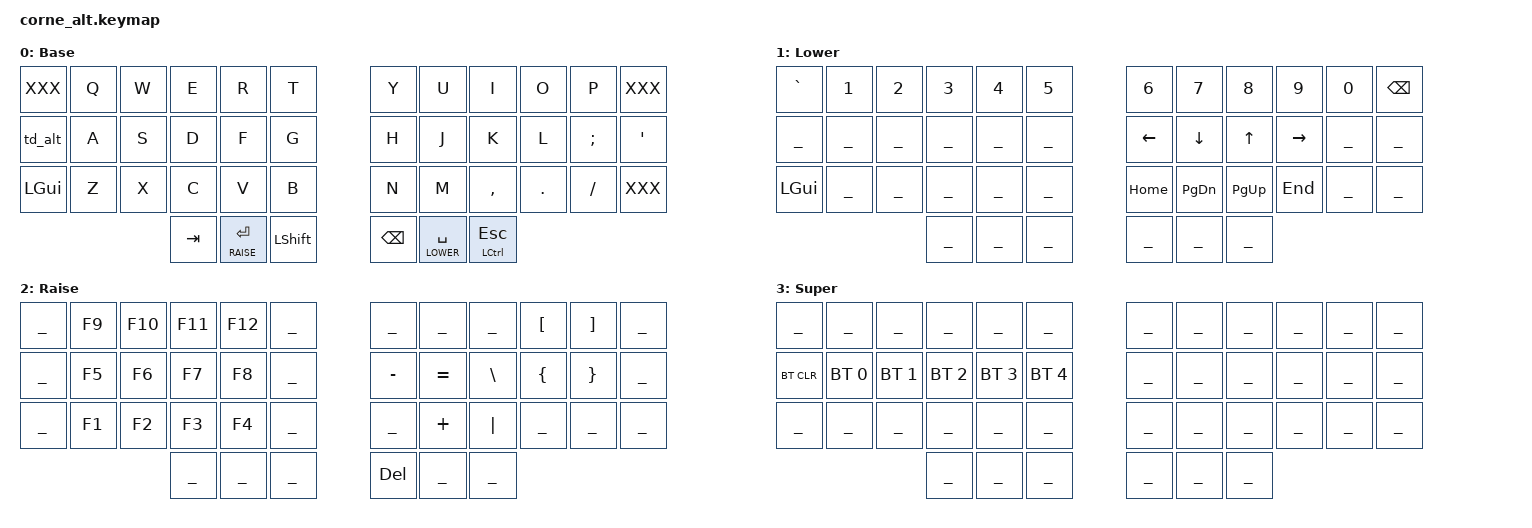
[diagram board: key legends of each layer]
/*
 * Copyright (c) 2020 The ZMK Contributors
 *
 * SPDX-License-Identifier: MIT
 */
 // https://caksoylar.github.io/keymap-drawer?keymap_yaml=H4sIAAAAAAAC_5WU23aTQBSG7_sU43hWGkNOLbhcS5qQtopGc7DWNCJNpk1WCCCQVbMivo0-g_e-mPPDdGxOrb3Il-GfvX82eza4zsyfxvoWIV8nY3vMZqe-Ew500vdDj9mhHzsxG4hdN4sllnHc6LTtKHBHsV38VrGLW3yLhRFsambd6FhtLAnZJl1v6roKoe8pxxFgAk2gDRwDHeAQaADvOJDXuzShluHG2DGAFlAD6sA-cAC8Al4DFvAceEivuOxPR9A-AR-BKvAB2APeAm8ABcgBz1aKaRsInvNOmF7MQoUMdf5EzihiNFFIazg6i2EYOH0m4lpYZ3GWf8FCxM35lVWNQ94dOLWqCe5gNY7MpmwecukXbhLx_x9pFhRVKHekUhDKS6kUhXJXKiWh3JNKWSj3pVIRymep7AjlgVR2hfJEKppQHkklL5THUBa6l83D9aQWO0uPu-ZfeOl8BOnQjM6HMb0aejvXA3_C0vE6JwNhzJfT1Nv0Buud08fJTjyeBUwnceh4UbLh_NcFiYFY3ZAjsryVXtIhcwdrB2UxAZU2jcOWufTK1TX-U_OAChSu6UwXLejRtU2tlxVC6hVgB9iVWdvIegGcnIBzINngoiK3ABSBknSxkfUU-E5Xi_ufc1hq16aW0xpzN72PK6Y39bzvT0799IO3TeaBTroqf6xiTyFj7vnnFzd0uUjF15DyDYcn-4FCfJ3kczzYCft21HdcbqrmCpXkn5WWOWVWv29nlc9ppWSxKu2yqp83WWlLVeXLyV_cwd0WIAYAAA%3D%3D

#include <behaviors.dtsi>
#include <dt-bindings/zmk/keys.h>
#include <dt-bindings/zmk/bt.h>

#include "../utils/keypos_42keys.h"

#define K_E LT2
#define K_O RT3
#define K_A LM4

#define DEFAULT 0
#define LOWER   1
#define RAISE   2
#define SUPER   3

#include "common.h"

COMBO(lnx_oe_comb, K_O K_E, DEFAULT, &lnx_no_oe)
COMBO(lnx_ae_comb, K_A K_E, DEFAULT, &lnx_no_ae)
COMBO(lnx_ao_comb, K_A K_O, DEFAULT, &lnx_no_ao)

/ {
        behaviors {
            kp_mo: behavior_kp_mo {
                compatible = "zmk,behavior-hold-tap";
                label = "kp_mo";
                #binding-cells = <2>;
                flavor = "hold-preferred";
                tapping-term-ms = <200>;
                bindings = <&mo>, <&kp>;
            };
            td_alt: td_alt {
                compatible = "zmk,behavior-tap-dance";
                label = "td_alt";
                #binding-cells = <0>;
                tapping-term-ms = <200>;
                bindings = <&kp LALT>, <&kp RALT>;
            };
        };
        keymap {
                compatible = "zmk,keymap";

                default_layer {
// ---------------------------------------------------------------------------------------
// |     |  Q  |  W  |  E  |  R  |    T    |   |    Y    |  U   |  I  |  O  |  P  |      |
// | ALT |  A  |  S  |  D  |  F  |    G    |   |    H    |  J   |  K  |  L  |  ;  |  '   |
// | GUI |  Z  |  X  |  C  |  V  |    B    |   |    N    |  M   |  ,  |  .  |  /  |      |
//                        | TAB |SHIFT| ENT/RSE |   | SPC/LWR | BKSP | CTRL/ESC |
                        label = "Base";
                        bindings = <
   XXX      &kp Q &kp W &kp E &kp R &kp T   &kp Y &kp U  &kp I     &kp O   &kp P    XXX
   &td_alt  &kp A &kp S &kp D &kp F &kp G   &kp H &kp J  &kp K     &kp L   &kp SEMI &kp SQT
   &kp LGUI &kp Z &kp X &kp C &kp V &kp B   &kp N &kp M  &kp COMMA &kp DOT &kp FSLH XXX
                      &kp TAB &kp_mo RAISE RET &kp LSHIFT &kp BSPC &kp_mo LOWER SPACE &mt LCTRL ESC
                        >;
                };
                lower_layer {
// ----------------------------------------------------------------------------------------
// |      |  1  |  2  |  3  |  4  |    5    |   |    6    |  7   |  8  |  9  |  0  |      |
// |      |     |     |     |     |         |   |   LFT   | DWN  |  UP | RGT |     |      |
// |      |     |     |     |     |         |   |   HME   | P_D  | P_U | END |     |      |
//                    |     |     |         |   |         |      |     |
                        label = "Lower";
                        bindings = <
   &kp GRAVE &kp N1 &kp N2 &kp N3 &kp N4 &kp N5 &kp N6   &kp N7    &kp N8    &kp N9    &kp N0 &kp BSPC
   ___       ___    ___    ___    ___    ___    &kp LEFT &kp DOWN  &kp UP    &kp RIGHT ___    ___
   &kp LGUI  ___    ___    ___    ___    ___    &kp HOME &kp PG_DN &kp PG_UP &kp END   ___    ___
                                  ___ ___ ___      ___  ___ ___
                        >;
                };
                raise_layer {
// ---------------------------------------------------------------------------------------
// |      | F9  | F10 | F11 | F12 |         |   |         |     |     |  [  |  ]  |      |
// |      | F5  | F6  |  F7 | F8  |         |   |    -    |  =  |  \  |  {  |  }  |      |
// |      | F1  | F2  |  F3 | F4  |         |   |    _    |  +  |  |  |     |     |      |
//                    |     |     |         |   |         |     |     |
                        label = "Raise";
                        bindings = <
   ___ &kp F9 &kp F10 &kp F11 &kp F12 ___ ___       ___       ___      &kp LBKT &kp RBKT ___
   ___ &kp F5 &kp F6  &kp F7  &kp F8  ___ &kp MINUS &kp EQUAL &kp BSLH &kp LBRC &kp RBRC ___
   ___ &kp F1 &kp F2  &kp F3  &kp F4  ___ &kp UNDER &kp PLUS  &kp PIPE ___      ___      ___
                                  ___ ___ ___      &kp DEL  ___ ___
                        >;
                };
                super {
// ----------------------------------------------------------------------------------------
// |      |     |     |     |     |         |   |         |      |     |     |     |      |
// | BTCLR| BT1 | BT2 | BT3 | BT4 |   BT5   |   |         |      |     |     |     |      |
// |      |     |     |     |     |         |   |         |      |     |     |     |      |
//                    |     |     |         |   |         |      |     |
                        label = "Super";
                        bindings = <
    ___        ___          ___          ___          ___          ___          ___ ___ ___ ___ ___ ___
    &bt BT_CLR &bt BT_SEL 0 &bt BT_SEL 1 &bt BT_SEL 2 &bt BT_SEL 3 &bt BT_SEL 4 ___ ___ ___ ___ ___ ___
    ___        ___          ___          ___          ___          ___          ___ ___ ___ ___ ___ ___
                                  ___ ___ ___      ___  ___ ___
                        >;
                };
        };
};

